# GD32H77x register map
File version: 1.0
CPU: CM7 r1p2, little endian, MPU, FPU, 4 interrupt priority bits
Registers are 32-bit, read-write, reset 0x0 unless marked. A register's access mark holds for its fields unless they carry their own. Offsets are from the block's base; [hi:lo] are bit positions; {n}, {i} and the like mark numbered series.

## RCU — Reset and clock unit
Base 0x58024400
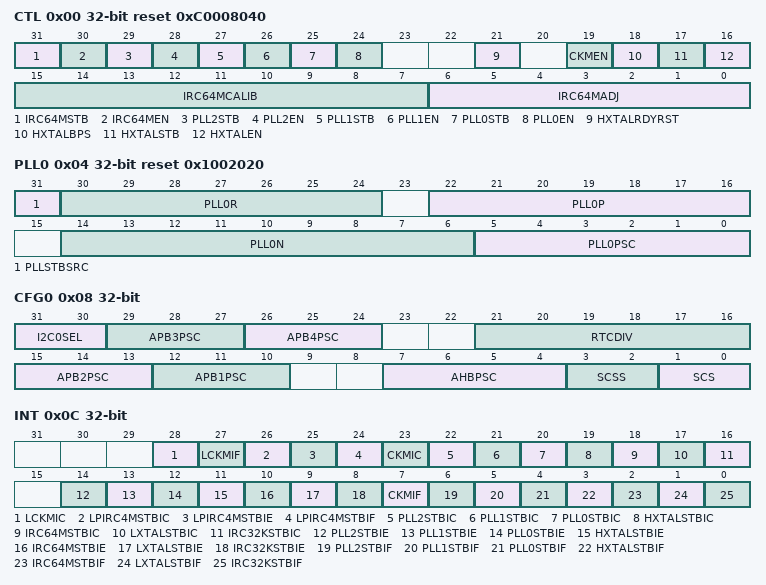
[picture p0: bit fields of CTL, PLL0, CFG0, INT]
0x00 CTL access per field reset 0xC0008040 — Control register
  [31] IRC64MSTB ro — IRC64M internal 64MHz RC oscillator stabilization flag
  [30] IRC64MEN rw — Internal 64MHz RC oscillator enable
  [29] PLL2STB ro — PLL2 clock stabilization flag
  [28] PLL2EN rw — PLL2 enable
  [27] PLL1STB ro — PLL1 clock stabilization flag
  [26] PLL1EN rw — PLL1 enable
  [25] PLL0STB ro — PLL0 clock stabilization flag
  [24] PLL0EN rw — PLL0 enable
  [21] HXTALRDYRST rw — HXTAL ready reset
  [19] CKMEN rw — HXTAL clock monitor enable
  [18] HXTALBPS rw — High speed crystal oscillator (HXTAL) clock bypass mode enable
  [17] HXTALSTB ro — High speed crystal oscillator (HXTAL) clock stabilization flag
  [16] HXTALEN rw — High speed crystal oscillator (HXTAL) enable
  [15:7] IRC64MCALIB ro — Internal 64MHz RC Oscillator calibration value
  [6:0] IRC64MADJ rw — Internal 64MHz RC Oscillator clock trim adjust value
0x04 PLL0 access per field reset 0x1002020
  [31] PLLSTBSRC wo — PLLs stabilization signal sources.
  [30:24] PLL0R rw — The PLL0R output frequency division factor from PLL0 VCO clock
  [22:16] PLL0P rw — The PLL0P output frequency division factor from PLL0 VCO clock
  [14:6] PLL0N rw — The PLL0 VCO clock multiplication factor
  [5:0] PLL0PSC rw — The PLL0 VCO source clock prescaler
0x08 CFG0 access per field — Clock configuration register 0
  [31:30] I2C0SEL rw — I2C0 clock source selection
  [29:27] APB3PSC rw — APB3 prescaler selection
  [26:24] APB4PSC rw — APB4 prescaler selection
  [21:16] RTCDIV rw — RTC clock divider factor
  [15:13] APB2PSC rw — APB2 prescaler selection
  [12:10] APB1PSC rw — APB1 prescaler selection
  [7:4] AHBPSC rw — AHB and AXI prescaler selection
  [3:2] SCSS ro — System clock switch status
  [1:0] SCS rw — System clock switch
0x0C INT access per field — Clock interrupt register
  [28] LCKMIC wo — LXTAL clock stuck interrupt clear
  [27] LCKMIF ro — LXTAL clock stuck interrupt flag
  [26] LPIRC4MSTBIC wo — LPIRC4M stabilization interrupt clear
  [25] LPIRC4MSTBIE rw — LPIRC4M stabilization interrupt enable
  [24] LPIRC4MSTBIF ro — LPIRC4M Clock Stuck Interrupt Flag
  [23] CKMIC wo — HXTAL clock stuck interrupt clear
  [22] PLL2STBIC wo — PLL2 stabilization interrupt clear
  [21] PLL1STBIC wo — PLL1 stabilization interrupt clear
  [20] PLL0STBIC wo — PLL0 stabilization interrupt clear
  [19] HXTALSTBIC wo — HXTAL stabilization interrupt clear
  [18] IRC64MSTBIC wo — IRC64M stabilization interrupt clear
  [17] LXTALSTBIC wo — LXTAL stabilization interrupt clear
  [16] IRC32KSTBIC wo — IRC32K stabilization interrupt clear
  [14] PLL2STBIE rw — PLL2 stabilization interrupt enable
  [13] PLL1STBIE rw — PLL1 stabilization interrupt enable
  [12] PLL0STBIE rw — PLL0 stabilization interrupt enable
  [11] HXTALSTBIE rw — HXTAL stabilization interrupt enable
  [10] IRC64MSTBIE rw — IRC64M stabilization interrupt enable
  [9] LXTALSTBIE rw — LXTAL stabilization interrupt enable
  [8] IRC32KSTBIE rw — IRC32K stabilization interrupt enable
  [7] CKMIF ro — HXTAL clock stuck interrupt flag
  [6] PLL2STBIF ro — PLL2 stabilization interrupt flag
  [5] PLL1STBIF ro — PLL1 stabilization interrupt flag
  [4] PLL0STBIF ro — PLL0 stabilization interrupt flag
  [3] HXTALSTBIF ro — HXTAL stabilization interrupt flag
  [2] IRC64MSTBIF ro — IRC64M stabilization interrupt flag
  [1] LXTALSTBIF ro — LXTAL stabilization interrupt flag
  [0] IRC32KSTBIF ro — IRC32K stabilization interrupt flag
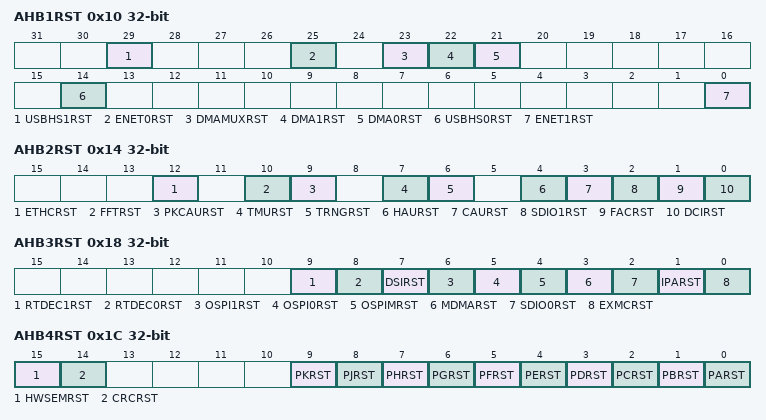
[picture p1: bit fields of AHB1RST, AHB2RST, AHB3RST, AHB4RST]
0x10 AHB1RST — AHB1 reset register
  [29] USBHS1RST — USBHS1 reset
  [25] ENET0RST — Ethernet0 reset
  [23] DMAMUXRST — DMAMUX reset
  [22] DMA1RST — DMA1 reset
  [21] DMA0RST — DMA0 reset
  [14] USBHS0RST — USBHS0 reset
  [0] ENET1RST — Ethernet1 reset
0x14 AHB2RST — AHB2 reset register
  [12] ETHCRST — ETHC reset
  [10] FFTRST — FFT reset
  [9] PKCAURST — PKCAU reset
  [7] TMURST — TMU reset
  [6] TRNGRST — TRNG reset
  [4] HAURST — HAU reset
  [3] CAURST — CAU reset
  [2] SDIO1RST — SDIO1 reset
  [1] FACRST — FAC reset
  [0] DCIRST — DCI reset
0x18 AHB3RST — AHB3 reset register
  [9] RTDEC1RST — RTDEC1 reset
  [8] RTDEC0RST — RTDEC0 reset
  [7] DSIRST — DSI reset
  [6] OSPI1RST — OSPI1 reset
  [5] OSPI0RST — OSPI0 reset
  [4] OSPIMRST — OSPIM reset
  [3] MDMARST — MDMA reset
  [2] SDIO0RST — SDIO0 reset
  [1] IPARST — IPA reset
  [0] EXMCRST — EXMC reset
0x1C AHB4RST — AHB4 reset register
  [15] HWSEMRST — HWSEM reset
  [14] CRCRST — CRC reset
  [9] PKRST — GPIO port K reset
  [8] PJRST — GPIO port J reset
  [7] PHRST — GPIO port H reset
  [6] PGRST — GPIO port G reset
  [5] PFRST — GPIO port F reset
  [4] PERST — GPIO port E reset
  [3] PDRST — GPIO port D reset
  [2] PCRST — GPIO port C reset
  [1] PBRST — GPIO port B reset
  [0] PARST — GPIO port A reset
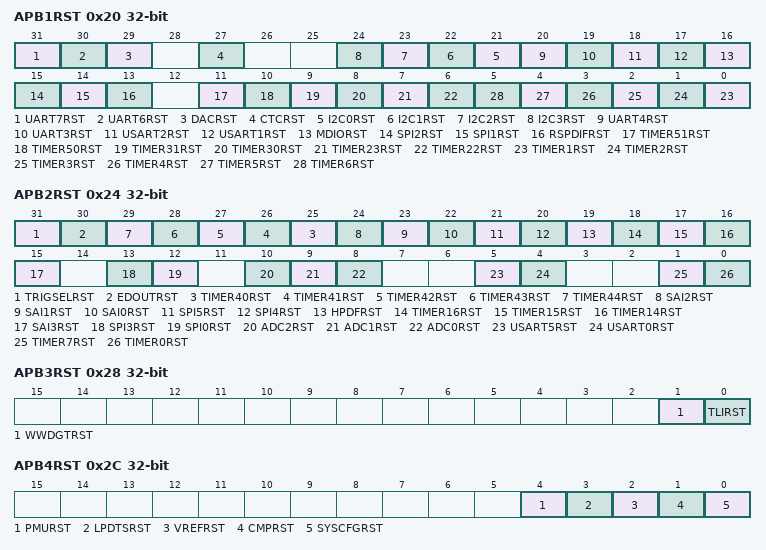
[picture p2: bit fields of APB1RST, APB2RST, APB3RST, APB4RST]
0x20 APB1RST — APB1 reset register
  [31] UART7RST — UART7 reset
  [30] UART6RST — UART6 reset
  [29] DACRST — DAC reset
  [27] CTCRST — CTC reset
  [n+21] I2C{n}RST (n=0..3) — I2C{n} reset
  [20] UART4RST — UART4 reset
  [19] UART3RST — UART3 reset
  [18] USART2RST — USART2 reset
  [17] USART1RST — USART1 reset
  [16] MDIORST — MDIO reset
  [15] SPI2RST — SPI2 reset
  [14] SPI1RST — SPI1 reset
  [13] RSPDIFRST — RSPDIF reset
  [11] TIMER51RST — TIMER51 reset
  [10] TIMER50RST — TIMER50 reset
  [9] TIMER31RST — TIMER31 reset
  [8] TIMER30RST — TIMER30 reset
  [7] TIMER23RST — TIMER23 reset
  [6] TIMER22RST — TIMER22 reset
  [n-1] TIMER{n}RST (n=1..6) — TIMER{n} reset
0x24 APB2RST — APB2 reset register
  [31] TRIGSELRST — TRIGSEL reset
  [30] EDOUTRST — EDOUT reset
  [n-15] TIMER{n}RST (n=40..44) — TIMER{n} reset
  [24] SAI2RST — SAI2 reset
  [23] SAI1RST — SAI1 reset
  [22] SAI0RST — SAI0 reset
  [21] SPI5RST — SPI5 reset
  [20] SPI4RST — SPI4 reset
  [19] HPDFRST — HPDF reset
  [18] TIMER16RST — TIMER16 reset
  [17] TIMER15RST — TIMER15 reset
  [16] TIMER14RST — TIMER14 reset
  [15] SAI3RST — SAI3 reset
  [13] SPI3RST — SPI3 reset
  [12] SPI0RST — SPI0 reset
  [10] ADC2RST — ADC2 reset
  [9] ADC1RST — ADC1 reset
  [8] ADC0RST — ADC0 reset
  [5] USART5RST — USART5 reset
  [4] USART0RST — USART0 reset
  [1] TIMER7RST — TIMER7 reset
  [0] TIMER0RST — TIMER0 reset
0x28 APB3RST — APB3 reset register
  [1] WWDGTRST — WWDGT reset
  [0] TLIRST — TLI reset
0x2C APB4RST — APB4 reset register
  [4] PMURST — PMU reset
  [3] LPDTSRST — LPDTS reset
  [2] VREFRST — VREF reset
  [1] CMPRST — CMP reset
  [0] SYSCFGRST — SYSCFG reset
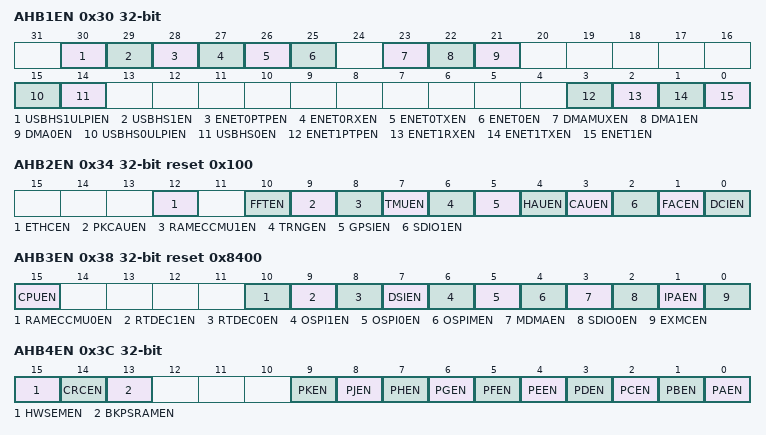
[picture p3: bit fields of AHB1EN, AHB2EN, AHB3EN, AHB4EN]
0x30 AHB1EN — AHB1 enable register
  [30] USBHS1ULPIEN — USBHS1 ULPI clock enable
  [29] USBHS1EN — USBHS1 clock enable
  [28] ENET0PTPEN — Ethernet0 PTP clock enable
  [27] ENET0RXEN — Ethernet0 RX clock enable
  [26] ENET0TXEN — Ethernet0 TX clock enable
  [25] ENET0EN — Ethernet0 clock enable
  [23] DMAMUXEN — DMAMUX clock enable
  [22] DMA1EN — DMA1 clock enable
  [21] DMA0EN — DMA0 clock enable
  [15] USBHS0ULPIEN — USBHS0 ULPI clock enable
  [14] USBHS0EN — USBHS0 clock enable
  [3] ENET1PTPEN — Ethernet1 PTP clock enable
  [2] ENET1RXEN — Ethernet1 RX clock enable
  [1] ENET1TXEN — Ethernet1 TX clock enable
  [0] ENET1EN — Ethernet1 clock enable
0x34 AHB2EN reset 0x100 — AHB2 enable register
  [12] ETHCEN — ETHC clock enable
  [10] FFTEN — FFT clock enable
  [9] PKCAUEN — PKCAU clock enable
  [8] RAMECCMU1EN — RAMECCMU1 clock enable
  [7] TMUEN — TMU clock enable
  [6] TRNGEN — TRNG clock enable
  [5] GPSIEN — GPSI clock enable
  [4] HAUEN — HAU clock enable
  [3] CAUEN — CAU clock enable
  [2] SDIO1EN — SDIO1 clock enable
  [1] FACEN — FAC clock enable
  [0] DCIEN — DCI clock enable
0x38 AHB3EN reset 0x8400 — AHB3 enable register
  [15] CPUEN — CPU clock enable
  [10] RAMECCMU0EN — RAMECCMU0 clock enable
  [9] RTDEC1EN — RTDEC1 clock enable
  [8] RTDEC0EN — RTDEC0 clock enable
  [7] DSIEN — DSI clock enable
  [6] OSPI1EN — OSPI1 clock enable
  [5] OSPI0EN — OSPI0 clock enable
  [4] OSPIMEN — OSPIM clock enable
  [3] MDMAEN — MDMA clock enable
  [2] SDIO0EN — SDIO0 clock enable
  [1] IPAEN — IPA clock enable
  [0] EXMCEN — EXMC clock enable
0x3C AHB4EN — AHB4 enable register
  [15] HWSEMEN — HWSEM clock enable
  [14] CRCEN — CRC clock enable
  [13] BKPSRAMEN — Backup SRAM clock enable
  [9] PKEN — GPIO port K clock enable
  [8] PJEN — GPIO port J clock enable
  [7] PHEN — GPIO port H clock enable
  [6] PGEN — GPIO port G clock enable
  [5] PFEN — GPIO port F clock enable
  [4] PEEN — GPIO port E clock enable
  [3] PDEN — GPIO port D clock enable
  [2] PCEN — GPIO port C clock enable
  [1] PBEN — GPIO port B clock enable
  [0] PAEN — GPIO port A clock enable
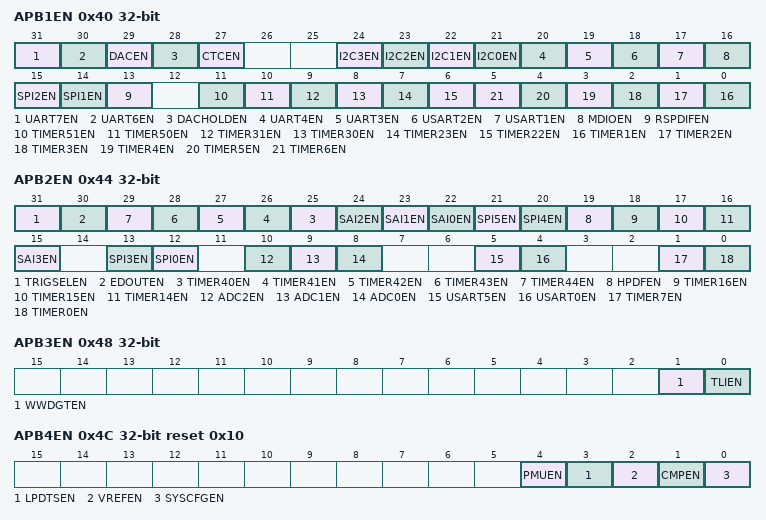
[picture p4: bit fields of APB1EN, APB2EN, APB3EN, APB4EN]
0x40 APB1EN — APB1 enable register
  [31] UART7EN — UART7 clock enable
  [30] UART6EN — UART6 clock enable
  [29] DACEN — DAC clock enable
  [28] DACHOLDEN — DAC hold clock enable
  [27] CTCEN — CTC clock enable
  [n+21] I2C{n}EN (n=0..3) — I2C{n} clock enable
  [20] UART4EN — UART4 clock enable
  [19] UART3EN — UART3 clock enable
  [18] USART2EN — USART2 clock enable
  [17] USART1EN — USART1 clock enable
  [16] MDIOEN — MDIO clock enable
  [15] SPI2EN — SPI2 clock enable
  [14] SPI1EN — SPI1 clock enable
  [13] RSPDIFEN — RSPDIF clock enable
  [11] TIMER51EN — TIMER51 clock enable
  [10] TIMER50EN — TIMER50 clock enable
  [9] TIMER31EN — TIMER31 clock enable
  [8] TIMER30EN — TIMER30 clock enable
  [7] TIMER23EN — TIMER23 clock enable
  [6] TIMER22EN — TIMER22 clock enable
  [n-1] TIMER{n}EN (n=1..6) — TIMER{n} clock enable
0x44 APB2EN — APB2 enable register
  [31] TRIGSELEN — TRIGSEL clock enable
  [30] EDOUTEN — EDOUT clock enable
  [n-15] TIMER{n}EN (n=40..44) — TIMER{n} clock enable
  [24] SAI2EN — SAI2 clock enable
  [23] SAI1EN — SAI1 clock enable
  [22] SAI0EN — SAI0 clock enable
  [21] SPI5EN — SPI5 clock enable
  [20] SPI4EN — SPI4 clock enable
  [19] HPDFEN — HPDF clock enable
  [18] TIMER16EN — TIMER16 clock enable
  [17] TIMER15EN — TIMER15 clock enable
  [16] TIMER14EN — TIMER14 clock enable
  [15] SAI3EN — SAI3 clock enable
  [13] SPI3EN — SPI3 clock enable
  [12] SPI0EN — SPI0 clock enable
  [10] ADC2EN — ADC2 clock enable
  [9] ADC1EN — ADC1 clock enable
  [8] ADC0EN — ADC0 clock enable
  [5] USART5EN — USART5 clock enable
  [4] USART0EN — USART0 clock enable
  [1] TIMER7EN — TIMER7 clock enable
  [0] TIMER0EN — TIMER0 clock enable
0x48 APB3EN — APB3 enable register
  [1] WWDGTEN — WWDGT clock enable
  [0] TLIEN — TLI clock enable
0x4C APB4EN reset 0x10 — APB4 enable register
  [4] PMUEN — PMU clock enable
  [3] LPDTSEN — LPDTS clock enable
  [2] VREFEN — VREF clock enable
  [1] CMPEN — CMP clock enable
  [0] SYSCFGEN — SYSCFG clock enable
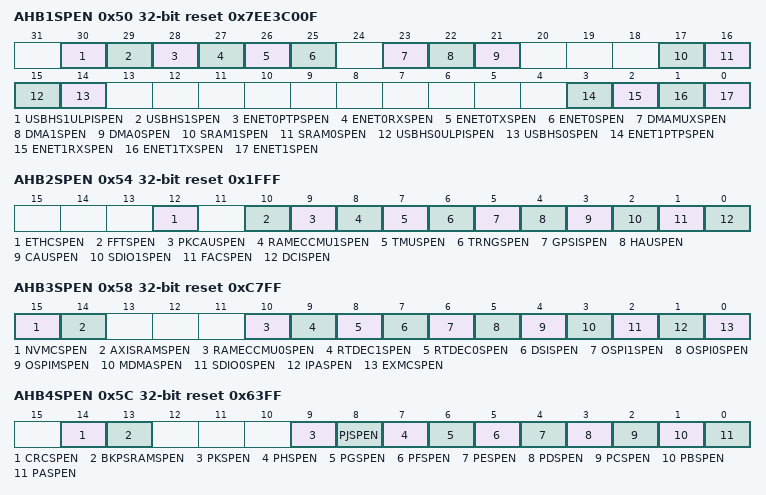
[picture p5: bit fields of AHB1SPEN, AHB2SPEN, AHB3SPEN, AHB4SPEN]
0x50 AHB1SPEN reset 0x7EE3C00F — AHB1 sleep mode enable register
  [30] USBHS1ULPISPEN — USBHS1 ULPI clock enable when sleep mode
  [29] USBHS1SPEN — USBHS1 clock enable when sleep mode
  [28] ENET0PTPSPEN — Ethernet0 PTP clock enable when sleep mode
  [27] ENET0RXSPEN — Ethernet0 RX clock enable when sleep mode
  [26] ENET0TXSPEN — Ethernet0 TX clock enable when sleep mode
  [25] ENET0SPEN — Ethernet0 clock enable when sleep mode
  [23] DMAMUXSPEN — DMAMUX clock enable when sleep mode
  [22] DMA1SPEN — DMA1 clock enable when sleep mode
  [21] DMA0SPEN — DMA0 clock enable when sleep mode
  [17] SRAM1SPEN — SRAM1 clock enable when sleep mode
  [16] SRAM0SPEN — SRAM0 clock enable when sleep mode
  [15] USBHS0ULPISPEN — USBHS0 ULPI clock enable when sleep mode
  [14] USBHS0SPEN — USBHS0 clock enable when sleep mode
  [3] ENET1PTPSPEN — Ethernet1 PTP clock enable when sleep mode
  [2] ENET1RXSPEN — Ethernet1 RX clock enable when sleep mode
  [1] ENET1TXSPEN — Ethernet1 TX clock enable when sleep mode
  [0] ENET1SPEN — Ethernet1 clock enable when sleep mode
0x54 AHB2SPEN reset 0x1FFF — AHB2 sleep mode enable register
  [12] ETHCSPEN — ETHC clock enable when sleep mode
  [10] FFTSPEN — FFT clock enable when sleep mode
  [9] PKCAUSPEN — PKCAU clock enable when sleep mode
  [8] RAMECCMU1SPEN — RAMECCMU1 clock enable when sleep mode
  [7] TMUSPEN — TMU clock enable when sleep mode
  [6] TRNGSPEN — TRNG clock enable when sleep mode
  [5] GPSISPEN — GPSI enable when sleep mode
  [4] HAUSPEN — HAU enable when sleep mode
  [3] CAUSPEN — CAU clock enable when sleep mode
  [2] SDIO1SPEN — SDIO1 clock enable when sleep mode
  [1] FACSPEN — FAC clock enable when sleep mode
  [0] DCISPEN — DCI clock enable when sleep mode
0x58 AHB3SPEN reset 0xC7FF — AHB3 sleep mode enable register
  [15] NVMCSPEN — NVMC clock enable when sleep mode
  [14] AXISRAMSPEN — AXI SRAM clock enable when sleep mode
  [10] RAMECCMU0SPEN — RAMECCMU0 clock enable when sleep mode
  [9] RTDEC1SPEN — RTDEC1 clock enable when sleep mode
  [8] RTDEC0SPEN — RTDEC0 clock enable when sleep mode
  [7] DSISPEN — DSI clock enable when sleep mode
  [6] OSPI1SPEN — OSPI1 clock enable when sleep mode
  [5] OSPI0SPEN — OSPI0 clock enable when sleep mode
  [4] OSPIMSPEN — OSPIM clock enable when sleep mode
  [3] MDMASPEN — MDMA clock enable when sleep mode
  [2] SDIO0SPEN — SDIO0 clock enable when sleep mode
  [1] IPASPEN — IPA clock enable when sleep mode
  [0] EXMCSPEN — EXMC clock enable when sleep mode
0x5C AHB4SPEN reset 0x63FF — AHB4 sleep mode enable register
  [14] CRCSPEN — CRC clock enable when sleep mode
  [13] BKPSRAMSPEN — Backup SRAM clock enable when sleep mode
  [9] PKSPEN — GPIO port K clock enable when sleep mode
  [8] PJSPEN — GPIO port J clock enable when sleep mode
  [7] PHSPEN — GPIO port H clock enable when sleep mode
  [6] PGSPEN — GPIO port G clock enable when sleep mode
  [5] PFSPEN — GPIO port F clock enable when sleep mode
  [4] PESPEN — GPIO port E clock enable when sleep mode
  [3] PDSPEN — GPIO port D clock enable when sleep mode
  [2] PCSPEN — GPIO port C clock enable when sleep mode
  [1] PBSPEN — GPIO port B clock enable when sleep mode
  [0] PASPEN — GPIO port A clock enable when sleep mode
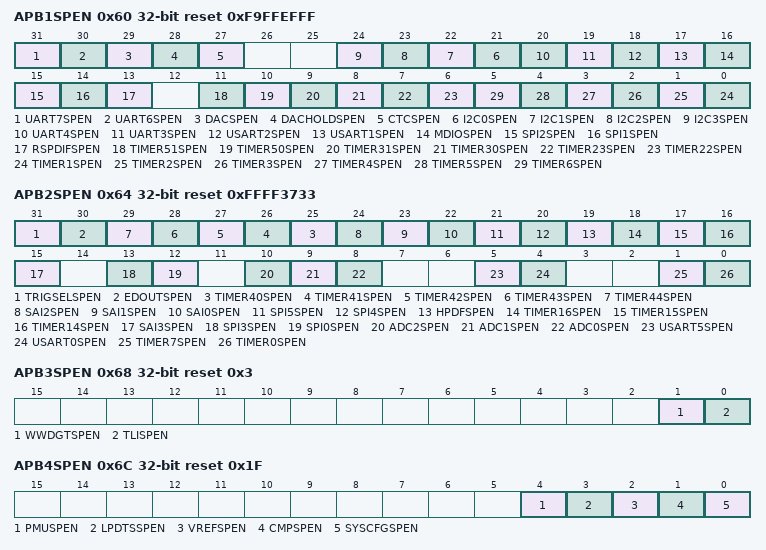
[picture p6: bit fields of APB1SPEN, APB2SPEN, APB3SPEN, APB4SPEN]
0x60 APB1SPEN reset 0xF9FFEFFF — APB1 sleep mode enable register
  [31] UART7SPEN — UART7 clock enable when sleep mode
  [30] UART6SPEN — UART6 clock enable when sleep mode
  [29] DACSPEN — DAC clock enable when sleep mode
  [28] DACHOLDSPEN — DAC hold clock enable when sleep mode
  [27] CTCSPEN — CTC clock enable when sleep mode
  [n+21] I2C{n}SPEN (n=0..3) — I2C{n} clock enable when sleep mode
  [20] UART4SPEN — UART4 clock enable when sleep mode
  [19] UART3SPEN — UART3 clock enable when sleep mode
  [18] USART2SPEN — USART2 clock enable when sleep mode
  [17] USART1SPEN — USART1 clock enable when sleep mode
  [16] MDIOSPEN — MDIO clock enable when sleep mode
  [15] SPI2SPEN — SPI2 clock enable when sleep mode
  [14] SPI1SPEN — SPI1 clock enable when sleep mode
  [13] RSPDIFSPEN — RSPDIF clock enable when sleep mode
  [11] TIMER51SPEN — TIMER51 clock enable when sleep mode
  [10] TIMER50SPEN — TIMER50 clock enable when sleep mode
  [9] TIMER31SPEN — TIMER31 clock enable when sleep mode
  [8] TIMER30SPEN — TIMER30 clock enable when sleep mode
  [7] TIMER23SPEN — TIMER23 clock enable when sleep mode
  [6] TIMER22SPEN — TIMER22 clock enable when sleep mode
  [n-1] TIMER{n}SPEN (n=1..6) — TIMER{n} clock enable when sleep mode
0x64 APB2SPEN reset 0xFFFF3733 — APB2 sleep mode enable register
  [31] TRIGSELSPEN — TRIGSEL clock enable when sleep mode
  [30] EDOUTSPEN — EDOUT clock enable when sleep mode
  [n-15] TIMER{n}SPEN (n=40..44) — TIMER{n} clock enable when sleep mode
  [24] SAI2SPEN — SAI2 clock enable when sleep mode
  [23] SAI1SPEN — SAI1 clock enable when sleep mode
  [22] SAI0SPEN — SAI0 clock enable when sleep mode
  [21] SPI5SPEN — SPI5 clock enable when sleep mode
  [20] SPI4SPEN — SPI4 clock enable when sleep mode
  [19] HPDFSPEN — HPDF clock enable when sleep mode
  [18] TIMER16SPEN — TIMER16 clock enable when sleep mode
  [17] TIMER15SPEN — TIMER15 clock enable when sleep mode
  [16] TIMER14SPEN — TIMER14 clock enable when sleep mode
  [15] SAI3SPEN — SAI3 clock enable when sleep mode
  [13] SPI3SPEN — SPI3 clock enable when sleep mode
  [12] SPI0SPEN — SPI0 clock enable when sleep mode
  [10] ADC2SPEN — ADC2 clock enable when sleep mode
  [9] ADC1SPEN — ADC1 clock enable when sleep mode
  [8] ADC0SPEN — ADC0 clock enable when sleep mode
  [5] USART5SPEN — USART5 clock enable when sleep mode
  [4] USART0SPEN — USART0 clock enable when sleep mode
  [1] TIMER7SPEN — TIMER7 clock enable when sleep mode
  [0] TIMER0SPEN — TIMER0 clock enable when sleep mode
0x68 APB3SPEN reset 0x3 — APB3 sleep mode enable register
  [1] WWDGTSPEN — WWDGT clock enable when sleep mode
  [0] TLISPEN — TLI clock enable when sleep mode
0x6C APB4SPEN reset 0x1F — APB4 sleep mode enable register
  [4] PMUSPEN — PMU clock enable when sleep mode
  [3] LPDTSSPEN — LPDTS clock enable when sleep mode
  [2] VREFSPEN — VREF clock enable when sleep mode
  [1] CMPSPEN — CMPclock enable when sleep mode
  [0] SYSCFGSPEN — SYSCFG clock enable when sleep mode
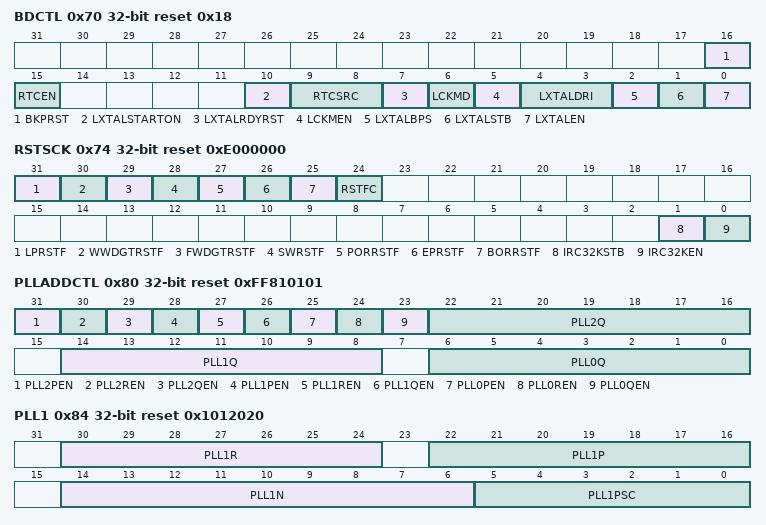
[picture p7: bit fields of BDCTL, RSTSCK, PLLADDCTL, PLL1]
0x70 BDCTL access per field reset 0x18 — Backup domain control register
  [16] BKPRST rw — Backup domain reset
  [15] RTCEN rw — RTC clock enable
  [10] LXTALSTARTON rw — LXTAL start circuit on control
  [9:8] RTCSRC rw — RTC clock entry selection
  [7] LXTALRDYRST rw — LXTAL ready reset
  [6] LCKMD ro — LXTAL clock failure detection
  [5] LCKMEN rw — LXTAL clock monitor enable
  [4:3] LXTALDRI rw — LXTAL drive capability
  [2] LXTALBPS rw — LXTAL bypass mode enable
  [1] LXTALSTB ro — Low speed crystal oscillator stabilization flag
  [0] LXTALEN rw — LXTAL enable
0x74 RSTSCK access per field reset 0xE000000 — Reset source/clock register
  [31] LPRSTF ro — Low-power reset flag
  [30] WWDGTRSTF ro — Window watchdog timer reset flag
  [29] FWDGTRSTF ro — Free watchdog timer reset flag
  [28] SWRSTF ro — Software reset flag
  [27] PORRSTF ro — Power reset flag
  [26] EPRSTF ro — External PIN reset flag
  [25] BORRSTF ro — BOR reset flag
  [24] RSTFC rw — Reset flag clear
  [1] IRC32KSTB ro — IRC32K stabilization flag
  [0] IRC32KEN rw — IRC32K enable
0x80 PLLADDCTL reset 0xFF810101 — PLL clock additional control register
  [31] PLL2PEN — PLL2P divider output enable
  [30] PLL2REN — PLL2R divider output enable
  [29] PLL2QEN — PLL2Q divider output enable
  [28] PLL1PEN — PLL1P divider output enable
  [27] PLL1REN — PLL1R divider output enable
  [26] PLL1QEN — PLL1Q divider output enable
  [25] PLL0PEN — PLL0P divider output enable
  [24] PLL0REN — PLL0R divider output enable
  [23] PLL0QEN — PLL0Q divider output enable
  [22:16] PLL2Q — The PLL2Q output frequency division factor from PLL2 VCO clock
  [14:8] PLL1Q — The PLL1Q output frequency division factor from PLL1 VCO clock
  [6:0] PLL0Q — The PLL0Q output frequency division factor from PLL0 VCO clock
0x84 PLL1 reset 0x1012020
  [30:24] PLL1R — The PLL1R output frequency division factor from PLL1 VCO clock
  [22:16] PLL1P — The PLL1P output frequency division factor from PLL1 VCO clock
  [14:6] PLL1N — The PLL1 VCO clock multiplication factor
  [5:0] PLL1PSC — The PLL1 VCO source clock prescaler
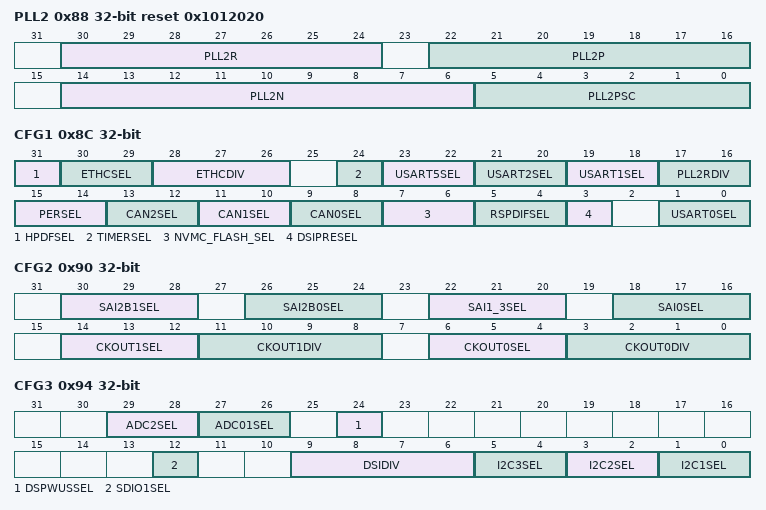
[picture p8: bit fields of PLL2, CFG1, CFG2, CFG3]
0x88 PLL2 reset 0x1012020
  [30:24] PLL2R — The PLL2R output frequency division factor from PLL2 VCO clock
  [22:16] PLL2P — The PLL2 P output frequency division factor from PLL2 VCO clock
  [14:6] PLL2N — The PLL2 VCO clock multiplication factor
  [5:0] PLL2PSC — The PLL2 VCO source clock prescaler
0x8C CFG1 — Clock configuration register 1
  [31] HPDFSEL — HPDF clock source selection
  [30:29] ETHCSEL — ETHC clock source selection
  [28:26] ETHCDIV — ETHC clock divider factor
  [24] TIMERSEL — TIMER clock selection
  [23:22] USART5SEL — USART5 clock source selection
  [21:20] USART2SEL — USART2 clock source selection
  [19:18] USART1SEL — USART1 clock source selection
  [17:16] PLL2RDIV — The divider factor from PLL2R clock
  [15:14] PERSEL — CK_PER clock selection
  [13:12] CAN2SEL — CAN2 clock source selection
  [11:10] CAN1SEL — CAN1 clock selection
  [9:8] CAN0SEL — CAN0 clock source selection
  [7:6] NVMC_FLASH_SEL — NVMC Flash clock source selection
  [5:4] RSPDIFSEL — RSPDIF clock source selection
  [3] DSIPRESEL — DSI preceding stage clock source selection
  [1:0] USART0SEL — USART0 clock source selection
0x90 CFG2 — Clock configuration register 2
  [30:28] SAI2B1SEL — SAI2 Block 1 clock source selection
  [26:24] SAI2B0SEL — SAI2 Block 0 clock source selection
  [22:20] SAI1_3SEL — SAI1 and SAI3 clock source selection
  [18:16] SAI0SEL — SA0 and HPDF audio clock source selection
  [14:12] CKOUT1SEL — CKOUT1 clock source selection
  [11:8] CKOUT1DIV — The CK_OUT1 divider which the CK_OUT1 frequency can be reduced
  [6:4] CKOUT0SEL — CKOUT0 clock source selection
  [3:0] CKOUT0DIV — The CK_OUT0 divider which the CK_OUT0 frequency can be reduced
0x94 CFG3 — Clock configuration register 3
  [29:28] ADC2SEL — ADC2 clock source selection
  [27:26] ADC01SEL — ADC0 and ADC1 clock source selection
  [24] DSPWUSSEL — Deep-sleep wakeup system clock source selection
  [12] SDIO1SEL — SDIO1 clock source selection
  [9:6] DSIDIV — DSI clock divider factor
  [5:4] I2C3SEL — I2C3 clock source selection
  [3:2] I2C2SEL — I2C2 clock source selection
  [1:0] I2C1SEL — I2C1 clock source selection
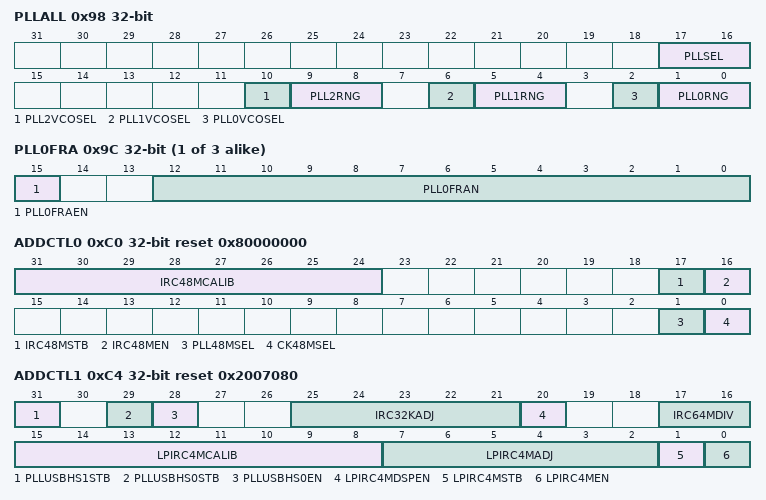
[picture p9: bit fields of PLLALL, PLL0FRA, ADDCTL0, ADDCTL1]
0x98 PLLALL — PLL all configuration register
  [17:16] PLLSEL — PLLs clock source selection
  [10] PLL2VCOSEL — PLL2 VCO selection
  [9:8] PLL2RNG — PLL2 input clock range
  [6] PLL1VCOSEL — PLL1 VCO selection
  [5:4] PLL1RNG — PLL1 input clock range
  [2] PLL0VCOSEL — PLL0 VCO selection
  [1:0] PLL0RNG — PLL0 input clock range
{0x9C+4i} PLL{i}FRA (i=0..2) — PLL{i} fraction configuration register
  [15] PLL{i}FRAEN — PLL{i} fractional latch enable.
  [12:0] PLL{i}FRAN — Fractional part of the multiplication factor for PLL{i} VCO
0xC0 ADDCTL0 access per field reset 0x80000000 — Additional clock control register 0
  [31:24] IRC48MCALIB ro — Internal 48MHz RC oscillator calibration value register
  [17] IRC48MSTB ro — Internal 48MHz RC oscillator clock stabilization Flag
  [16] IRC48MEN rw — Internal 48MHz RC oscillator enable
  [1] PLL48MSEL rw — PLL48M clock selection
  [0] CK48MSEL rw — 48MHz clock selection
0xC4 ADDCTL1 access per field reset 0x2007080 — Additional clock control register
  [31] PLLUSBHS1STB ro — PLLUSBHS1 clock stabilization flag
  [29] PLLUSBHS0STB ro — PLLUSBHS0 clock stabilization flag
  [28] PLLUSBHS0EN rw — PLLUSBHS0 clock enable
  [25:21] IRC32KADJ rw — IRC32K frequency clock trim adjust value
  [20] LPIRC4MDSPEN rw — LPIRC4M clock enable in deepsleep mode
  [17:16] IRC64MDIV rw — IRC64M clock divider
  [15:8] LPIRC4MCALIB ro — LPIRC4M calibration value
  [7:2] LPIRC4MADJ rw — LPIRC4M frequency clock trim adjust value
  [1] LPIRC4MSTB ro — LPIRC4M clock stabilization flag
  [0] LPIRC4MEN rw — LPIRC4M clock enable
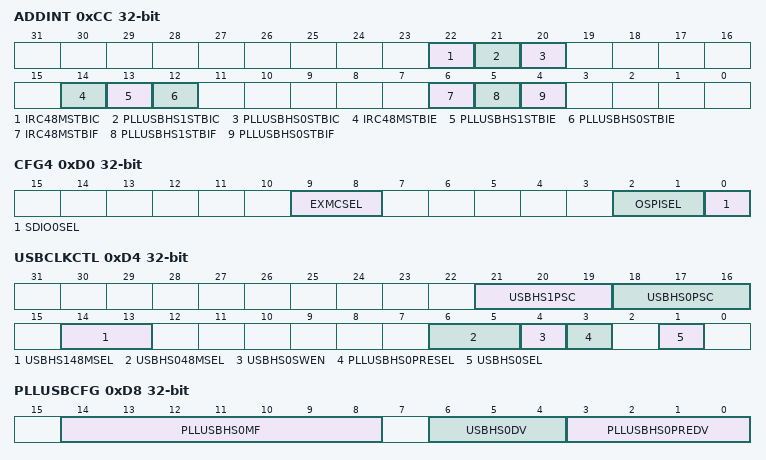
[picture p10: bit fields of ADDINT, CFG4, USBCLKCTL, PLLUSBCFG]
0xCC ADDINT access per field — Additional clock interrupt register
  [22] IRC48MSTBIC wo — Internal 48 MHz RC oscillator Stabilization interrupt clear
  [21] PLLUSBHS1STBIC wo — Internal PLL of USBHS1 Stabilization interrupt clear
  [20] PLLUSBHS0STBIC wo — Internal PLL of USBHS0 Stabilization interrupt clear
  [14] IRC48MSTBIE rw — Internal 48 MHz RC oscillator Stabilization interrupt enable
  [13] PLLUSBHS1STBIE rw — Internal PLL of USBHS1 Stabilization interrupt enable
  [12] PLLUSBHS0STBIE rw — Internal PLL of USBHS0 Stabilization interrupt enable
  [6] IRC48MSTBIF ro — IRC48M stabilization interrupt flag
  [5] PLLUSBHS1STBIF ro — Internal PLL of USBHS1 stabilization interrupt flag
  [4] PLLUSBHS0STBIF ro — Internal PLL of USBHS0 stabilization interrupt flag
0xD0 CFG4 — Clock configuration register 4
  [9:8] EXMCSEL — EXMC clock source selection
  [2:1] OSPISEL — OSPI clock source selection
  [0] SDIO0SEL — SDIO0 clock source selection
0xD4 USBCLKCTL — USB clock control register
  [21:19] USBHS1PSC — USBHS1 clock prescaler selection
  [18:16] USBHS0PSC — USBHS0 clock prescaler selection
  [14:13] USBHS148MSEL — USBHS1 48M clock source selection
  [6:5] USBHS048MSEL — USBHS0 48M clock source selection
  [4] USBHS0SWEN — USBHS0 clock source selection enable
  [3] PLLUSBHS0PRESEL — PLLUSBHS0 clock source preselection
  [1] USBHS0SEL — USBHS0 clock source selection
0xD8 PLLUSBCFG — PLLUSB configuration register
  [14:8] PLLUSBHS0MF — The PLLUSBHS0 clock multiplication factor
  [6:4] USBHS0DV — USBHS0 clock divider factor
  [3:0] PLLUSBHS0PREDV — PLLUSBHS0PREDV clock divide factor
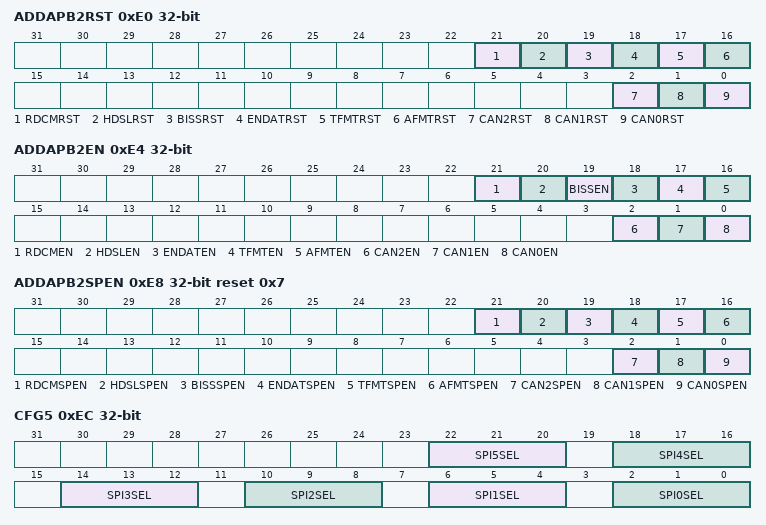
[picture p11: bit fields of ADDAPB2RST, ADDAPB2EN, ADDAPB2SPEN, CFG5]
0xE0 ADDAPB2RST — APB2 additional reset register
  [21] RDCMRST — RDCM reset
  [20] HDSLRST — HDSL reset
  [19] BISSRST — BISS reset
  [18] ENDATRST — ENDAT reset
  [17] TFMTRST — TFMT reset
  [16] AFMTRST — AFMT reset
  [2] CAN2RST — CAN2 reset
  [1] CAN1RST — CAN1 reset
  [0] CAN0RST — CAN0 reset
0xE4 ADDAPB2EN — APB2 additional enable register
  [21] RDCMEN — RDCM clock enable
  [20] HDSLEN — HDSL clock enable
  [19] BISSEN — BISS clock enable
  [18] ENDATEN — ENDAT clock enable
  [17] TFMTEN — TFMT clock enable
  [16] AFMTEN — AFMT clock enable
  [2] CAN2EN — CAN2 clock enable
  [1] CAN1EN — CAN1 clock enable
  [0] CAN0EN — CAN0 clock enable
0xE8 ADDAPB2SPEN reset 0x7 — APB2 additional sleep enable register
  [21] RDCMSPEN — RDCM clock enable in sleep mode
  [20] HDSLSPEN — HDSL clock enable in sleep mode
  [19] BISSSPEN — BISS clock enable in sleep mode
  [18] ENDATSPEN — ENDAT clock enable in sleep mode
  [17] TFMTSPEN — TFMT clock enable in sleep mode
  [16] AFMTSPEN — AFMT clock enable in sleep mode
  [2] CAN2SPEN — CAN2 clock enable in sleep mode
  [1] CAN1SPEN — CAN1 clock enable in sleep mode
  [0] CAN0SPEN — CAN0 clock enable in sleep mode
0xEC CFG5 — Clock configuration register 5
  [22:20] SPI5SEL — SPI5 / I2S5 clock source selection
  [18:16] SPI4SEL — SPI4 clock source selection
  [14:12] SPI3SEL — SPI3 clock source selection
  [10:8] SPI2SEL — SPI2 / I2S2 clock source selection
  [6:4] SPI1SEL — SPI1 / I2S1 clock source selection
  [2:0] SPI0SEL — SPI0 / I2S0 clock source selection
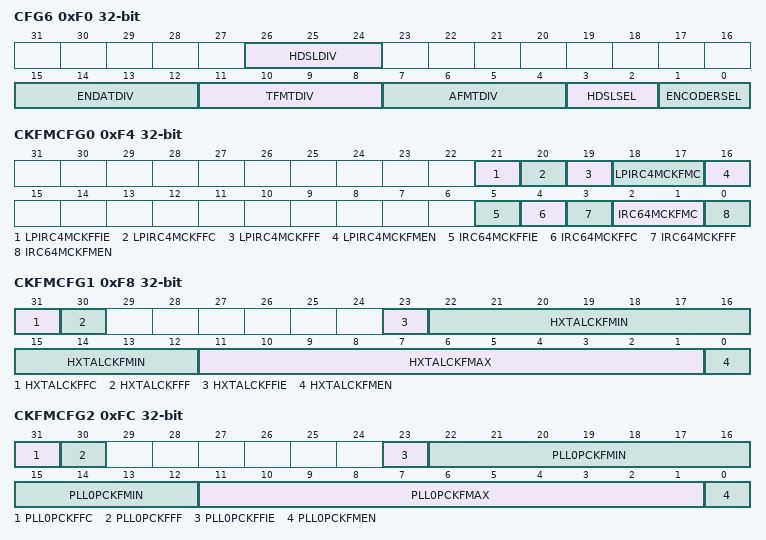
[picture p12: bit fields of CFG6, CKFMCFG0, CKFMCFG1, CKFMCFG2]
0xF0 CFG6 — Clock configuration register 6
  [26:24] HDSLDIV — HDSL divider
  [15:12] ENDATDIV — ENDAT divider
  [11:8] TFMTDIV — TFMT divider
  [7:4] AFMTDIV — AFMTdivider
  [3:2] HDSLSEL — HDSL clock source selection select
  [1:0] ENCODERSEL — ENCODER clock source selection select
0xF4 CKFMCFG0 access per field — Clock frequency monitor configuration register 0
  [21] LPIRC4MCKFFIE rw — LPIRC4M clock frequency failure interrupt enable
  [20] LPIRC4MCKFFC rw — LPIRC4M clock frequency failure flag clear
  [19] LPIRC4MCKFFF ro — LPIRC4M clock frequency failure flag
  [18:17] LPIRC4MCKFMC rw — LPIRC4M clock frequency monitor configuration
  [16] LPIRC4MCKFMEN rw — LPIRC4M clock frequency monitor enable
  [5] IRC64MCKFFIE rw — IRC64M clock frequency failure interrupt enable
  [4] IRC64MCKFFC rw — IRC64M clock frequency failure flag clear
  [3] IRC64MCKFFF ro — IRC64M clock frequency failure flag
  [2:1] IRC64MCKFMC rw — IRC64M clock frequency monitor configuration
  [0] IRC64MCKFMEN rw — IRC64M clock frequency monitor enable
0xF8 CKFMCFG1 access per field — Clock frequency monitor configuration register 1
  [31] HXTALCKFFC rw — HXTAL clock frequency failure flag clear
  [30] HXTALCKFFF ro — HXTAL clock frequency failure flag
  [23] HXTALCKFFIE rw — HXTAL clock frequency failure interrupt enable
  [22:12] HXTALCKFMIN rw — HXTAL clock frequency monitor configuration minimum value
  [11:1] HXTALCKFMAX rw — HXTAL clock frequency monitor configuration maximum value
  [0] HXTALCKFMEN rw — HXTAL clock frequency monitor enable
0xFC CKFMCFG2 access per field — Clock frequency monitor configuration register 2
  [31] PLL0PCKFFC rw — PLL0P clock frequency failure flag clear
  [30] PLL0PCKFFF ro — PLL0P clock frequency failure flag
  [23] PLL0PCKFFIE rw — PLL0P clock frequency failure interrupt enable
  [22:12] PLL0PCKFMIN rw — PLL0P clock frequency monitor configuration minimum value
  [11:1] PLL0PCKFMAX rw — PLL0P clock frequency monitor configuration maximum value
  [0] PLL0PCKFMEN rw — PLL0P clock frequency monitor enable
